# PIC32MK0512GPK100 device description
Architecture: MIPS; Family: PIC32MK; Series: PIC32MK
Registers are 32-bit, read-write, no defined reset value unless marked. A register's access mark holds for its fields unless they carry their own. Offsets are from the block's base; [hi:lo] are bit positions; 'fields as' and 'values as' point back to an identical list.

## GPIO
Instances: GPIO 0x1f860000 in periph_pb4_std
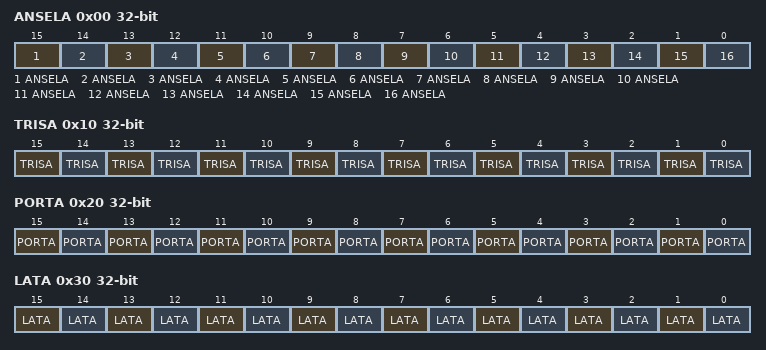
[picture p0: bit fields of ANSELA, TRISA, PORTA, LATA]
0x00 ANSELA
  [15] ANSELA, [14] ANSELA, [13] ANSELA, [12] ANSELA, [11] ANSELA, [10] ANSELA, [9] ANSELA, [8] ANSELA, [7] ANSELA, [6] ANSELA, [5] ANSELA, [4] ANSELA, [3] ANSELA, [2] ANSELA, [1] ANSELA, [0] ANSELA
0x10 TRISA
  [15] TRISA, [14] TRISA, [13] TRISA, [12] TRISA, [11] TRISA, [10] TRISA, [9] TRISA, [8] TRISA, [7] TRISA, [6] TRISA, [5] TRISA, [4] TRISA, [3] TRISA, [2] TRISA, [1] TRISA, [0] TRISA
0x20 PORTA
  [15] PORTA, [14] PORTA, [13] PORTA, [12] PORTA, [11] PORTA, [10] PORTA, [9] PORTA, [8] PORTA, [7] PORTA, [6] PORTA, [5] PORTA, [4] PORTA, [3] PORTA, [2] PORTA, [1] PORTA, [0] PORTA
0x30 LATA
  [15] LATA, [14] LATA, [13] LATA, [12] LATA, [11] LATA, [10] LATA, [9] LATA, [8] LATA, [7] LATA, [6] LATA, [5] LATA, [4] LATA, [3] LATA, [2] LATA, [1] LATA, [0] LATA
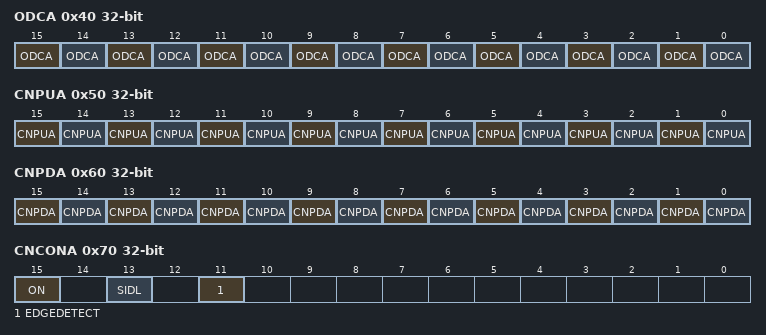
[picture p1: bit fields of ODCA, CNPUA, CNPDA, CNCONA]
0x40 ODCA
  [15] ODCA, [14] ODCA, [13] ODCA, [12] ODCA, [11] ODCA, [10] ODCA, [9] ODCA, [8] ODCA, [7] ODCA, [6] ODCA, [5] ODCA, [4] ODCA, [3] ODCA, [2] ODCA, [1] ODCA, [0] ODCA
0x50 CNPUA
  [15] CNPUA, [14] CNPUA, [13] CNPUA, [12] CNPUA, [11] CNPUA, [10] CNPUA, [9] CNPUA, [8] CNPUA, [7] CNPUA, [6] CNPUA, [5] CNPUA, [4] CNPUA, [3] CNPUA, [2] CNPUA, [1] CNPUA, [0] CNPUA
0x60 CNPDA
  [15] CNPDA, [14] CNPDA, [13] CNPDA, [12] CNPDA, [11] CNPDA, [10] CNPDA, [9] CNPDA, [8] CNPDA, [7] CNPDA, [6] CNPDA, [5] CNPDA, [4] CNPDA, [3] CNPDA, [2] CNPDA, [1] CNPDA, [0] CNPDA
0x70 CNCONA — Change Notice control for PORTx Register
  [15] ON — Change Notice Control ON bit
    1=CN is enabled; 0=CN is disabled
  [13] SIDL — Stop in Idle Control bit
    1=CPU Idle mode halts CN operation; 0=CPU Idle mode does not affect CN operation
  [11] EDGEDETECT — Change Notification Style bit
    1=Edge Style. Detect edge transitions (CNFx used for CN Event).; 0=Mismatch Style. Detect change from last PORTx read (CNSTATx used for CN Event).
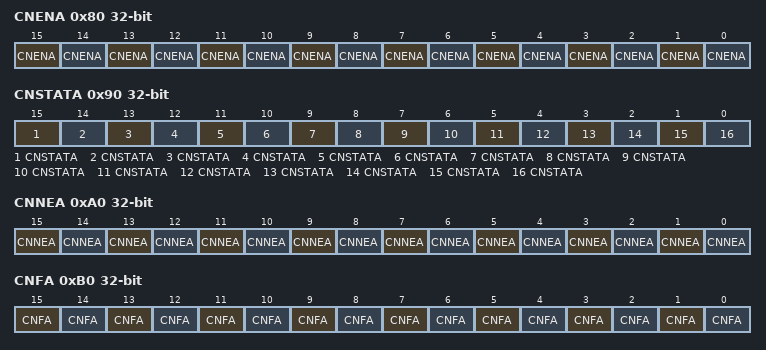
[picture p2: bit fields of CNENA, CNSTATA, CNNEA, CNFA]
0x80 CNENA
  [15] CNENA, [14] CNENA, [13] CNENA, [12] CNENA, [11] CNENA, [10] CNENA, [9] CNENA, [8] CNENA, [7] CNENA, [6] CNENA, [5] CNENA, [4] CNENA, [3] CNENA, [2] CNENA, [1] CNENA, [0] CNENA
0x90 CNSTATA
  [15] CNSTATA, [14] CNSTATA, [13] CNSTATA, [12] CNSTATA, [11] CNSTATA, [10] CNSTATA, [9] CNSTATA, [8] CNSTATA, [7] CNSTATA, [6] CNSTATA, [5] CNSTATA, [4] CNSTATA, [3] CNSTATA, [2] CNSTATA, [1] CNSTATA, [0] CNSTATA
0xA0 CNNEA
  [15] CNNEA, [14] CNNEA, [13] CNNEA, [12] CNNEA, [11] CNNEA, [10] CNNEA, [9] CNNEA, [8] CNNEA, [7] CNNEA, [6] CNNEA, [5] CNNEA, [4] CNNEA, [3] CNNEA, [2] CNNEA, [1] CNNEA, [0] CNNEA
0xB0 CNFA
  [15] CNFA, [14] CNFA, [13] CNFA, [12] CNFA, [11] CNFA, [10] CNFA, [9] CNFA, [8] CNFA, [7] CNFA, [6] CNFA, [5] CNFA, [4] CNFA, [3] CNFA, [2] CNFA, [1] CNFA, [0] CNFA
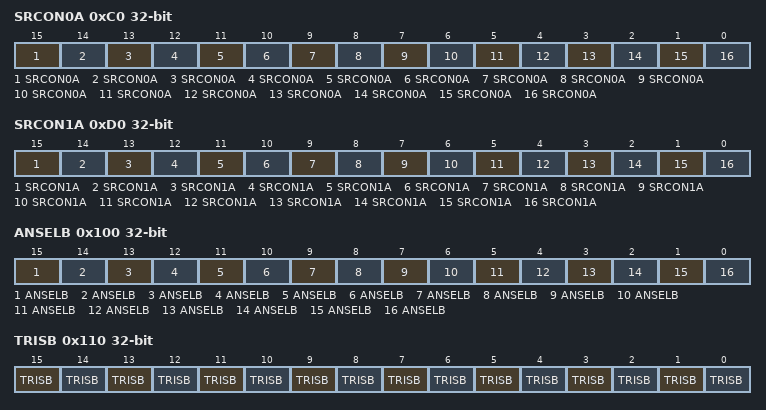
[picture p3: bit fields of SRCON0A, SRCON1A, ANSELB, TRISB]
0xC0 SRCON0A
  [15] SRCON0A, [14] SRCON0A, [13] SRCON0A, [12] SRCON0A, [11] SRCON0A, [10] SRCON0A, [9] SRCON0A, [8] SRCON0A, [7] SRCON0A, [6] SRCON0A, [5] SRCON0A, [4] SRCON0A, [3] SRCON0A, [2] SRCON0A, [1] SRCON0A, [0] SRCON0A
0xD0 SRCON1A
  [15] SRCON1A, [14] SRCON1A, [13] SRCON1A, [12] SRCON1A, [11] SRCON1A, [10] SRCON1A, [9] SRCON1A, [8] SRCON1A, [7] SRCON1A, [6] SRCON1A, [5] SRCON1A, [4] SRCON1A, [3] SRCON1A, [2] SRCON1A, [1] SRCON1A, [0] SRCON1A
0x100 ANSELB
  [15] ANSELB, [14] ANSELB, [13] ANSELB, [12] ANSELB, [11] ANSELB, [10] ANSELB, [9] ANSELB, [8] ANSELB, [7] ANSELB, [6] ANSELB, [5] ANSELB, [4] ANSELB, [3] ANSELB, [2] ANSELB, [1] ANSELB, [0] ANSELB
0x110 TRISB
  [15] TRISB, [14] TRISB, [13] TRISB, [12] TRISB, [11] TRISB, [10] TRISB, [9] TRISB, [8] TRISB, [7] TRISB, [6] TRISB, [5] TRISB, [4] TRISB, [3] TRISB, [2] TRISB, [1] TRISB, [0] TRISB
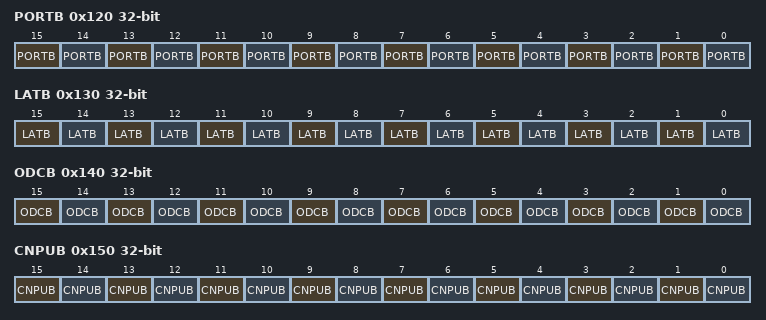
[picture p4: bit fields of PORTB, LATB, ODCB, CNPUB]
0x120 PORTB
  [15] PORTB, [14] PORTB, [13] PORTB, [12] PORTB, [11] PORTB, [10] PORTB, [9] PORTB, [8] PORTB, [7] PORTB, [6] PORTB, [5] PORTB, [4] PORTB, [3] PORTB, [2] PORTB, [1] PORTB, [0] PORTB
0x130 LATB
  [15] LATB, [14] LATB, [13] LATB, [12] LATB, [11] LATB, [10] LATB, [9] LATB, [8] LATB, [7] LATB, [6] LATB, [5] LATB, [4] LATB, [3] LATB, [2] LATB, [1] LATB, [0] LATB
0x140 ODCB
  [15] ODCB, [14] ODCB, [13] ODCB, [12] ODCB, [11] ODCB, [10] ODCB, [9] ODCB, [8] ODCB, [7] ODCB, [6] ODCB, [5] ODCB, [4] ODCB, [3] ODCB, [2] ODCB, [1] ODCB, [0] ODCB
0x150 CNPUB
  [15] CNPUB, [14] CNPUB, [13] CNPUB, [12] CNPUB, [11] CNPUB, [10] CNPUB, [9] CNPUB, [8] CNPUB, [7] CNPUB, [6] CNPUB, [5] CNPUB, [4] CNPUB, [3] CNPUB, [2] CNPUB, [1] CNPUB, [0] CNPUB
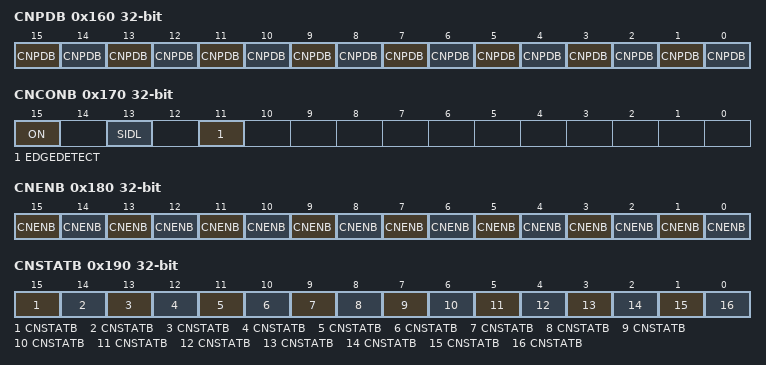
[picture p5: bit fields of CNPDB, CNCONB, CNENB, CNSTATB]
0x160 CNPDB
  [15] CNPDB, [14] CNPDB, [13] CNPDB, [12] CNPDB, [11] CNPDB, [10] CNPDB, [9] CNPDB, [8] CNPDB, [7] CNPDB, [6] CNPDB, [5] CNPDB, [4] CNPDB, [3] CNPDB, [2] CNPDB, [1] CNPDB, [0] CNPDB
0x170 CNCONB — Change Notice control for PORTx Register
  fields as CNCONA
0x180 CNENB
  [15] CNENB, [14] CNENB, [13] CNENB, [12] CNENB, [11] CNENB, [10] CNENB, [9] CNENB, [8] CNENB, [7] CNENB, [6] CNENB, [5] CNENB, [4] CNENB, [3] CNENB, [2] CNENB, [1] CNENB, [0] CNENB
0x190 CNSTATB
  [15] CNSTATB, [14] CNSTATB, [13] CNSTATB, [12] CNSTATB, [11] CNSTATB, [10] CNSTATB, [9] CNSTATB, [8] CNSTATB, [7] CNSTATB, [6] CNSTATB, [5] CNSTATB, [4] CNSTATB, [3] CNSTATB, [2] CNSTATB, [1] CNSTATB, [0] CNSTATB
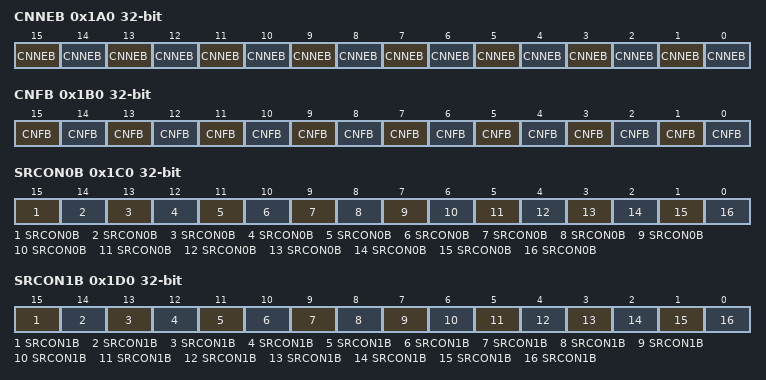
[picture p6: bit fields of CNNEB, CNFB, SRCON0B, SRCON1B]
0x1A0 CNNEB
  [15] CNNEB, [14] CNNEB, [13] CNNEB, [12] CNNEB, [11] CNNEB, [10] CNNEB, [9] CNNEB, [8] CNNEB, [7] CNNEB, [6] CNNEB, [5] CNNEB, [4] CNNEB, [3] CNNEB, [2] CNNEB, [1] CNNEB, [0] CNNEB
0x1B0 CNFB
  [15] CNFB, [14] CNFB, [13] CNFB, [12] CNFB, [11] CNFB, [10] CNFB, [9] CNFB, [8] CNFB, [7] CNFB, [6] CNFB, [5] CNFB, [4] CNFB, [3] CNFB, [2] CNFB, [1] CNFB, [0] CNFB
0x1C0 SRCON0B
  [15] SRCON0B, [14] SRCON0B, [13] SRCON0B, [12] SRCON0B, [11] SRCON0B, [10] SRCON0B, [9] SRCON0B, [8] SRCON0B, [7] SRCON0B, [6] SRCON0B, [5] SRCON0B, [4] SRCON0B, [3] SRCON0B, [2] SRCON0B, [1] SRCON0B, [0] SRCON0B
0x1D0 SRCON1B
  [15] SRCON1B, [14] SRCON1B, [13] SRCON1B, [12] SRCON1B, [11] SRCON1B, [10] SRCON1B, [9] SRCON1B, [8] SRCON1B, [7] SRCON1B, [6] SRCON1B, [5] SRCON1B, [4] SRCON1B, [3] SRCON1B, [2] SRCON1B, [1] SRCON1B, [0] SRCON1B
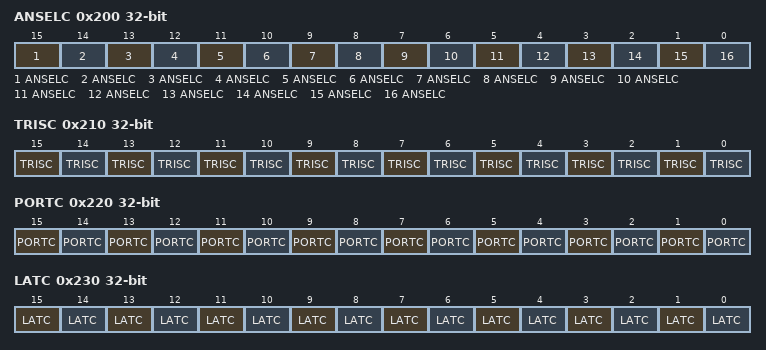
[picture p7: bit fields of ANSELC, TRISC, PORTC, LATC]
0x200 ANSELC
  [15] ANSELC, [14] ANSELC, [13] ANSELC, [12] ANSELC, [11] ANSELC, [10] ANSELC, [9] ANSELC, [8] ANSELC, [7] ANSELC, [6] ANSELC, [5] ANSELC, [4] ANSELC, [3] ANSELC, [2] ANSELC, [1] ANSELC, [0] ANSELC
0x210 TRISC
  [15] TRISC, [14] TRISC, [13] TRISC, [12] TRISC, [11] TRISC, [10] TRISC, [9] TRISC, [8] TRISC, [7] TRISC, [6] TRISC, [5] TRISC, [4] TRISC, [3] TRISC, [2] TRISC, [1] TRISC, [0] TRISC
0x220 PORTC
  [15] PORTC, [14] PORTC, [13] PORTC, [12] PORTC, [11] PORTC, [10] PORTC, [9] PORTC, [8] PORTC, [7] PORTC, [6] PORTC, [5] PORTC, [4] PORTC, [3] PORTC, [2] PORTC, [1] PORTC, [0] PORTC
0x230 LATC
  [15] LATC, [14] LATC, [13] LATC, [12] LATC, [11] LATC, [10] LATC, [9] LATC, [8] LATC, [7] LATC, [6] LATC, [5] LATC, [4] LATC, [3] LATC, [2] LATC, [1] LATC, [0] LATC
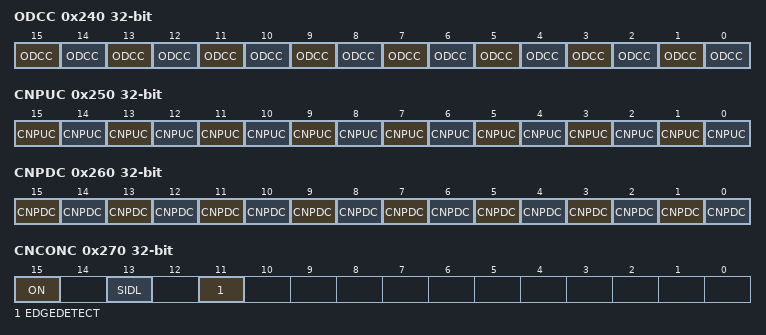
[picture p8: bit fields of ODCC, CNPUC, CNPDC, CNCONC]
0x240 ODCC
  [15] ODCC, [14] ODCC, [13] ODCC, [12] ODCC, [11] ODCC, [10] ODCC, [9] ODCC, [8] ODCC, [7] ODCC, [6] ODCC, [5] ODCC, [4] ODCC, [3] ODCC, [2] ODCC, [1] ODCC, [0] ODCC
0x250 CNPUC
  [15] CNPUC, [14] CNPUC, [13] CNPUC, [12] CNPUC, [11] CNPUC, [10] CNPUC, [9] CNPUC, [8] CNPUC, [7] CNPUC, [6] CNPUC, [5] CNPUC, [4] CNPUC, [3] CNPUC, [2] CNPUC, [1] CNPUC, [0] CNPUC
0x260 CNPDC
  [15] CNPDC, [14] CNPDC, [13] CNPDC, [12] CNPDC, [11] CNPDC, [10] CNPDC, [9] CNPDC, [8] CNPDC, [7] CNPDC, [6] CNPDC, [5] CNPDC, [4] CNPDC, [3] CNPDC, [2] CNPDC, [1] CNPDC, [0] CNPDC
0x270 CNCONC — Change Notice control for PORTx Register
  fields as CNCONA
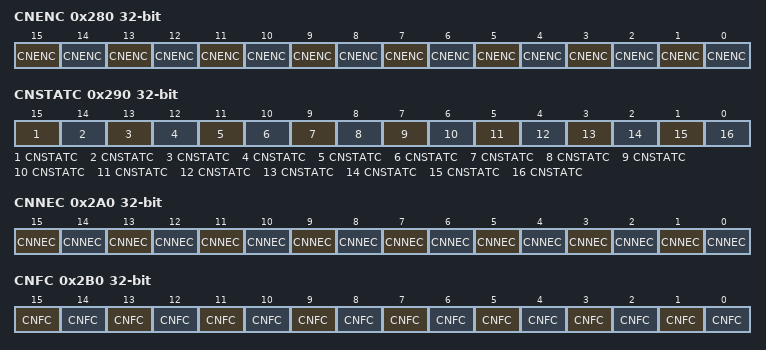
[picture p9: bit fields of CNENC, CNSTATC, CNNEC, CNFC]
0x280 CNENC
  [15] CNENC, [14] CNENC, [13] CNENC, [12] CNENC, [11] CNENC, [10] CNENC, [9] CNENC, [8] CNENC, [7] CNENC, [6] CNENC, [5] CNENC, [4] CNENC, [3] CNENC, [2] CNENC, [1] CNENC, [0] CNENC
0x290 CNSTATC
  [15] CNSTATC, [14] CNSTATC, [13] CNSTATC, [12] CNSTATC, [11] CNSTATC, [10] CNSTATC, [9] CNSTATC, [8] CNSTATC, [7] CNSTATC, [6] CNSTATC, [5] CNSTATC, [4] CNSTATC, [3] CNSTATC, [2] CNSTATC, [1] CNSTATC, [0] CNSTATC
0x2A0 CNNEC
  [15] CNNEC, [14] CNNEC, [13] CNNEC, [12] CNNEC, [11] CNNEC, [10] CNNEC, [9] CNNEC, [8] CNNEC, [7] CNNEC, [6] CNNEC, [5] CNNEC, [4] CNNEC, [3] CNNEC, [2] CNNEC, [1] CNNEC, [0] CNNEC
0x2B0 CNFC
  [15] CNFC, [14] CNFC, [13] CNFC, [12] CNFC, [11] CNFC, [10] CNFC, [9] CNFC, [8] CNFC, [7] CNFC, [6] CNFC, [5] CNFC, [4] CNFC, [3] CNFC, [2] CNFC, [1] CNFC, [0] CNFC
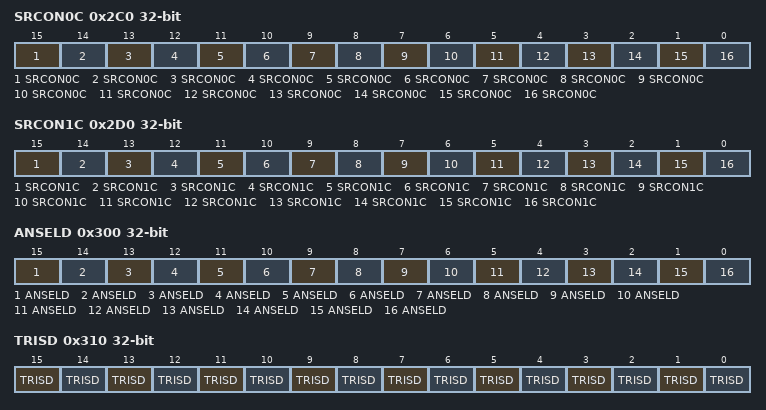
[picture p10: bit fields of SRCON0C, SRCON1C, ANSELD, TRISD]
0x2C0 SRCON0C
  [15] SRCON0C, [14] SRCON0C, [13] SRCON0C, [12] SRCON0C, [11] SRCON0C, [10] SRCON0C, [9] SRCON0C, [8] SRCON0C, [7] SRCON0C, [6] SRCON0C, [5] SRCON0C, [4] SRCON0C, [3] SRCON0C, [2] SRCON0C, [1] SRCON0C, [0] SRCON0C
0x2D0 SRCON1C
  [15] SRCON1C, [14] SRCON1C, [13] SRCON1C, [12] SRCON1C, [11] SRCON1C, [10] SRCON1C, [9] SRCON1C, [8] SRCON1C, [7] SRCON1C, [6] SRCON1C, [5] SRCON1C, [4] SRCON1C, [3] SRCON1C, [2] SRCON1C, [1] SRCON1C, [0] SRCON1C
0x300 ANSELD
  [15] ANSELD, [14] ANSELD, [13] ANSELD, [12] ANSELD, [11] ANSELD, [10] ANSELD, [9] ANSELD, [8] ANSELD, [7] ANSELD, [6] ANSELD, [5] ANSELD, [4] ANSELD, [3] ANSELD, [2] ANSELD, [1] ANSELD, [0] ANSELD
0x310 TRISD
  [15] TRISD, [14] TRISD, [13] TRISD, [12] TRISD, [11] TRISD, [10] TRISD, [9] TRISD, [8] TRISD, [7] TRISD, [6] TRISD, [5] TRISD, [4] TRISD, [3] TRISD, [2] TRISD, [1] TRISD, [0] TRISD
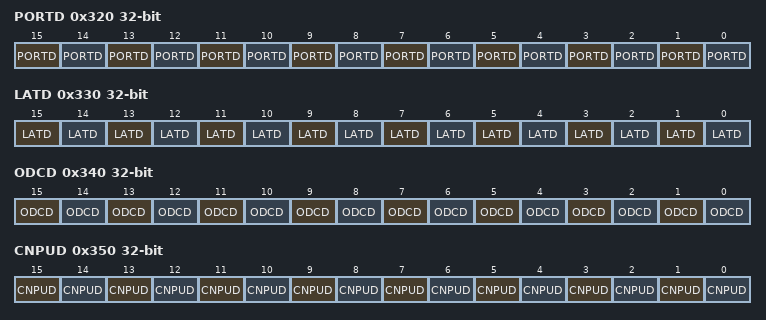
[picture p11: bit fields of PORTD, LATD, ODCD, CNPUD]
0x320 PORTD
  [15] PORTD, [14] PORTD, [13] PORTD, [12] PORTD, [11] PORTD, [10] PORTD, [9] PORTD, [8] PORTD, [7] PORTD, [6] PORTD, [5] PORTD, [4] PORTD, [3] PORTD, [2] PORTD, [1] PORTD, [0] PORTD
0x330 LATD
  [15] LATD, [14] LATD, [13] LATD, [12] LATD, [11] LATD, [10] LATD, [9] LATD, [8] LATD, [7] LATD, [6] LATD, [5] LATD, [4] LATD, [3] LATD, [2] LATD, [1] LATD, [0] LATD
0x340 ODCD
  [15] ODCD, [14] ODCD, [13] ODCD, [12] ODCD, [11] ODCD, [10] ODCD, [9] ODCD, [8] ODCD, [7] ODCD, [6] ODCD, [5] ODCD, [4] ODCD, [3] ODCD, [2] ODCD, [1] ODCD, [0] ODCD
0x350 CNPUD
  [15] CNPUD, [14] CNPUD, [13] CNPUD, [12] CNPUD, [11] CNPUD, [10] CNPUD, [9] CNPUD, [8] CNPUD, [7] CNPUD, [6] CNPUD, [5] CNPUD, [4] CNPUD, [3] CNPUD, [2] CNPUD, [1] CNPUD, [0] CNPUD
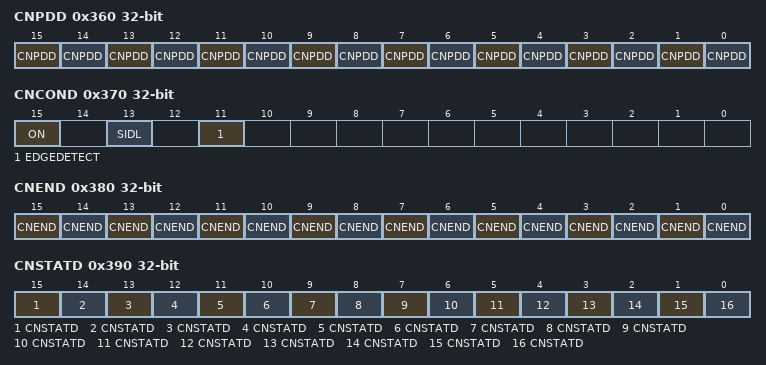
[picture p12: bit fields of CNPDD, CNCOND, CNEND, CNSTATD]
0x360 CNPDD
  [15] CNPDD, [14] CNPDD, [13] CNPDD, [12] CNPDD, [11] CNPDD, [10] CNPDD, [9] CNPDD, [8] CNPDD, [7] CNPDD, [6] CNPDD, [5] CNPDD, [4] CNPDD, [3] CNPDD, [2] CNPDD, [1] CNPDD, [0] CNPDD
0x370 CNCOND — Change Notice control for PORTx Register
  fields as CNCONA
0x380 CNEND
  [15] CNEND, [14] CNEND, [13] CNEND, [12] CNEND, [11] CNEND, [10] CNEND, [9] CNEND, [8] CNEND, [7] CNEND, [6] CNEND, [5] CNEND, [4] CNEND, [3] CNEND, [2] CNEND, [1] CNEND, [0] CNEND
0x390 CNSTATD
  [15] CNSTATD, [14] CNSTATD, [13] CNSTATD, [12] CNSTATD, [11] CNSTATD, [10] CNSTATD, [9] CNSTATD, [8] CNSTATD, [7] CNSTATD, [6] CNSTATD, [5] CNSTATD, [4] CNSTATD, [3] CNSTATD, [2] CNSTATD, [1] CNSTATD, [0] CNSTATD
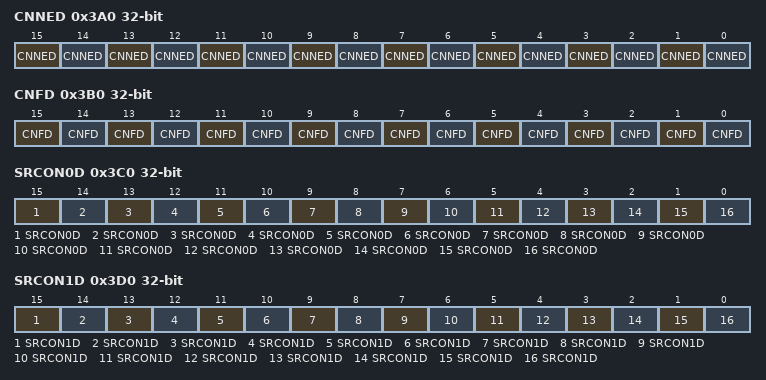
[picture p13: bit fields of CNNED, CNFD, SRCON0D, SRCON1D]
0x3A0 CNNED
  [15] CNNED, [14] CNNED, [13] CNNED, [12] CNNED, [11] CNNED, [10] CNNED, [9] CNNED, [8] CNNED, [7] CNNED, [6] CNNED, [5] CNNED, [4] CNNED, [3] CNNED, [2] CNNED, [1] CNNED, [0] CNNED
0x3B0 CNFD
  [15] CNFD, [14] CNFD, [13] CNFD, [12] CNFD, [11] CNFD, [10] CNFD, [9] CNFD, [8] CNFD, [7] CNFD, [6] CNFD, [5] CNFD, [4] CNFD, [3] CNFD, [2] CNFD, [1] CNFD, [0] CNFD
0x3C0 SRCON0D
  [15] SRCON0D, [14] SRCON0D, [13] SRCON0D, [12] SRCON0D, [11] SRCON0D, [10] SRCON0D, [9] SRCON0D, [8] SRCON0D, [7] SRCON0D, [6] SRCON0D, [5] SRCON0D, [4] SRCON0D, [3] SRCON0D, [2] SRCON0D, [1] SRCON0D, [0] SRCON0D
0x3D0 SRCON1D
  [15] SRCON1D, [14] SRCON1D, [13] SRCON1D, [12] SRCON1D, [11] SRCON1D, [10] SRCON1D, [9] SRCON1D, [8] SRCON1D, [7] SRCON1D, [6] SRCON1D, [5] SRCON1D, [4] SRCON1D, [3] SRCON1D, [2] SRCON1D, [1] SRCON1D, [0] SRCON1D
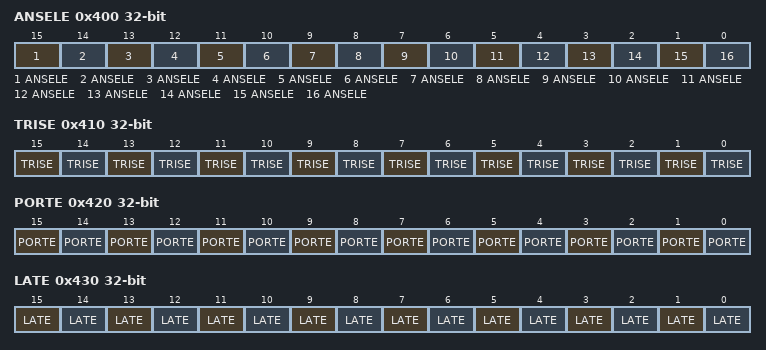
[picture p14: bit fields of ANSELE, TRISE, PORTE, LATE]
0x400 ANSELE
  [15] ANSELE, [14] ANSELE, [13] ANSELE, [12] ANSELE, [11] ANSELE, [10] ANSELE, [9] ANSELE, [8] ANSELE, [7] ANSELE, [6] ANSELE, [5] ANSELE, [4] ANSELE, [3] ANSELE, [2] ANSELE, [1] ANSELE, [0] ANSELE
0x410 TRISE
  [15] TRISE, [14] TRISE, [13] TRISE, [12] TRISE, [11] TRISE, [10] TRISE, [9] TRISE, [8] TRISE, [7] TRISE, [6] TRISE, [5] TRISE, [4] TRISE, [3] TRISE, [2] TRISE, [1] TRISE, [0] TRISE
0x420 PORTE
  [15] PORTE, [14] PORTE, [13] PORTE, [12] PORTE, [11] PORTE, [10] PORTE, [9] PORTE, [8] PORTE, [7] PORTE, [6] PORTE, [5] PORTE, [4] PORTE, [3] PORTE, [2] PORTE, [1] PORTE, [0] PORTE
0x430 LATE
  [15] LATE, [14] LATE, [13] LATE, [12] LATE, [11] LATE, [10] LATE, [9] LATE, [8] LATE, [7] LATE, [6] LATE, [5] LATE, [4] LATE, [3] LATE, [2] LATE, [1] LATE, [0] LATE
0x440 ODCE
  [15] ODCE, [14] ODCE, [13] ODCE, [12] ODCE, [11] ODCE, [10] ODCE, [9] ODCE, [8] ODCE, [7] ODCE, [6] ODCE, [5] ODCE, [4] ODCE, [3] ODCE, [2] ODCE, [1] ODCE, [0] ODCE
0x450 CNPUE
  [15] CNPUE, [14] CNPUE, [13] CNPUE, [12] CNPUE, [11] CNPUE, [10] CNPUE, [9] CNPUE, [8] CNPUE, [7] CNPUE, [6] CNPUE, [5] CNPUE, [4] CNPUE, [3] CNPUE, [2] CNPUE, [1] CNPUE, [0] CNPUE
0x460 CNPDE
  [15] CNPDE, [14] CNPDE, [13] CNPDE, [12] CNPDE, [11] CNPDE, [10] CNPDE, [9] CNPDE, [8] CNPDE, [7] CNPDE, [6] CNPDE, [5] CNPDE, [4] CNPDE, [3] CNPDE, [2] CNPDE, [1] CNPDE, [0] CNPDE
0x470 CNCONE — Change Notice control for PORTx Register
  fields as CNCONA
0x480 CNENE
  [15] CNENE, [14] CNENE, [13] CNENE, [12] CNENE, [11] CNENE, [10] CNENE, [9] CNENE, [8] CNENE, [7] CNENE, [6] CNENE, [5] CNENE, [4] CNENE, [3] CNENE, [2] CNENE, [1] CNENE, [0] CNENE
0x490 CNSTATE
  [15] CNSTATE, [14] CNSTATE, [13] CNSTATE, [12] CNSTATE, [11] CNSTATE, [10] CNSTATE, [9] CNSTATE, [8] CNSTATE, [7] CNSTATE, [6] CNSTATE, [5] CNSTATE, [4] CNSTATE, [3] CNSTATE, [2] CNSTATE, [1] CNSTATE, [0] CNSTATE
0x4A0 CNNEE
  [15] CNNEE, [14] CNNEE, [13] CNNEE, [12] CNNEE, [11] CNNEE, [10] CNNEE, [9] CNNEE, [8] CNNEE, [7] CNNEE, [6] CNNEE, [5] CNNEE, [4] CNNEE, [3] CNNEE, [2] CNNEE, [1] CNNEE, [0] CNNEE
0x4B0 CNFE
  [15] CNFE, [14] CNFE, [13] CNFE, [12] CNFE, [11] CNFE, [10] CNFE, [9] CNFE, [8] CNFE, [7] CNFE, [6] CNFE, [5] CNFE, [4] CNFE, [3] CNFE, [2] CNFE, [1] CNFE, [0] CNFE
0x4C0 SRCON0E
  [15] SRCON0E, [14] SRCON0E, [13] SRCON0E, [12] SRCON0E, [11] SRCON0E, [10] SRCON0E, [9] SRCON0E, [8] SRCON0E, [7] SRCON0E, [6] SRCON0E, [5] SRCON0E, [4] SRCON0E, [3] SRCON0E, [2] SRCON0E, [1] SRCON0E, [0] SRCON0E
0x4D0 SRCON1E
  [15] SRCON1E, [14] SRCON1E, [13] SRCON1E, [12] SRCON1E, [11] SRCON1E, [10] SRCON1E, [9] SRCON1E, [8] SRCON1E, [7] SRCON1E, [6] SRCON1E, [5] SRCON1E, [4] SRCON1E, [3] SRCON1E, [2] SRCON1E, [1] SRCON1E, [0] SRCON1E
0x500 ANSELF
  [15] ANSELF, [14] ANSELF, [13] ANSELF, [12] ANSELF, [11] ANSELF, [10] ANSELF, [9] ANSELF, [8] ANSELF, [7] ANSELF, [6] ANSELF, [5] ANSELF, [4] ANSELF, [3] ANSELF, [2] ANSELF, [1] ANSELF, [0] ANSELF
0x510 TRISF
  [15] TRISF, [14] TRISF, [13] TRISF, [12] TRISF, [11] TRISF, [10] TRISF, [9] TRISF, [8] TRISF, [7] TRISF, [6] TRISF, [5] TRISF, [4] TRISF, [3] TRISF, [2] TRISF, [1] TRISF, [0] TRISF
0x520 PORTF
  [15] PORTF, [14] PORTF, [13] PORTF, [12] PORTF, [11] PORTF, [10] PORTF, [9] PORTF, [8] PORTF, [7] PORTF, [6] PORTF, [5] PORTF, [4] PORTF, [3] PORTF, [2] PORTF, [1] PORTF, [0] PORTF
0x530 LATF
  [15] LATF, [14] LATF, [13] LATF, [12] LATF, [11] LATF, [10] LATF, [9] LATF, [8] LATF, [7] LATF, [6] LATF, [5] LATF, [4] LATF, [3] LATF, [2] LATF, [1] LATF, [0] LATF
0x540 ODCF
  [15] ODCF, [14] ODCF, [13] ODCF, [12] ODCF, [11] ODCF, [10] ODCF, [9] ODCF, [8] ODCF, [7] ODCF, [6] ODCF, [5] ODCF, [4] ODCF, [3] ODCF, [2] ODCF, [1] ODCF, [0] ODCF
0x550 CNPUF
  [15] CNPUF, [14] CNPUF, [13] CNPUF, [12] CNPUF, [11] CNPUF, [10] CNPUF, [9] CNPUF, [8] CNPUF, [7] CNPUF, [6] CNPUF, [5] CNPUF, [4] CNPUF, [3] CNPUF, [2] CNPUF, [1] CNPUF, [0] CNPUF
0x560 CNPDF
  [15] CNPDF, [14] CNPDF, [13] CNPDF, [12] CNPDF, [11] CNPDF, [10] CNPDF, [9] CNPDF, [8] CNPDF, [7] CNPDF, [6] CNPDF, [5] CNPDF, [4] CNPDF, [3] CNPDF, [2] CNPDF, [1] CNPDF, [0] CNPDF
0x570 CNCONF — Change Notice control for PORTx Register
  fields as CNCONA
0x580 CNENF
  [15] CNENF, [14] CNENF, [13] CNENF, [12] CNENF, [11] CNENF, [10] CNENF, [9] CNENF, [8] CNENF, [7] CNENF, [6] CNENF, [5] CNENF, [4] CNENF, [3] CNENF, [2] CNENF, [1] CNENF, [0] CNENF
0x590 CNSTATF
  [15] CNSTATF, [14] CNSTATF, [13] CNSTATF, [12] CNSTATF, [11] CNSTATF, [10] CNSTATF, [9] CNSTATF, [8] CNSTATF, [7] CNSTATF, [6] CNSTATF, [5] CNSTATF, [4] CNSTATF, [3] CNSTATF, [2] CNSTATF, [1] CNSTATF, [0] CNSTATF
0x5A0 CNNEF
  [15] CNNEF, [14] CNNEF, [13] CNNEF, [12] CNNEF, [11] CNNEF, [10] CNNEF, [9] CNNEF, [8] CNNEF, [7] CNNEF, [6] CNNEF, [5] CNNEF, [4] CNNEF, [3] CNNEF, [2] CNNEF, [1] CNNEF, [0] CNNEF
0x5B0 CNFF
  [15] CNFF, [14] CNFF, [13] CNFF, [12] CNFF, [11] CNFF, [10] CNFF, [9] CNFF, [8] CNFF, [7] CNFF, [6] CNFF, [5] CNFF, [4] CNFF, [3] CNFF, [2] CNFF, [1] CNFF, [0] CNFF
0x5C0 SRCON0F
  [15] SRCON0F, [14] SRCON0F, [13] SRCON0F, [12] SRCON0F, [11] SRCON0F, [10] SRCON0F, [9] SRCON0F, [8] SRCON0F, [7] SRCON0F, [6] SRCON0F, [5] SRCON0F, [4] SRCON0F, [3] SRCON0F, [2] SRCON0F, [1] SRCON0F, [0] SRCON0F
0x5D0 SRCON1F
  [15] SRCON1F, [14] SRCON1F, [13] SRCON1F, [12] SRCON1F, [11] SRCON1F, [10] SRCON1F, [9] SRCON1F, [8] SRCON1F, [7] SRCON1F, [6] SRCON1F, [5] SRCON1F, [4] SRCON1F, [3] SRCON1F, [2] SRCON1F, [1] SRCON1F, [0] SRCON1F
0x600 ANSELG
  [15] ANSELG, [14] ANSELG, [13] ANSELG, [12] ANSELG, [11] ANSELG, [10] ANSELG, [9] ANSELG, [8] ANSELG, [7] ANSELG, [6] ANSELG, [5] ANSELG, [4] ANSELG, [3] ANSELG, [2] ANSELG, [1] ANSELG, [0] ANSELG
0x610 TRISG
  [15] TRISG, [14] TRISG, [13] TRISG, [12] TRISG, [11] TRISG, [10] TRISG, [9] TRISG, [8] TRISG, [7] TRISG, [6] TRISG, [5] TRISG, [4] TRISG, [3] TRISG, [2] TRISG, [1] TRISG, [0] TRISG
0x620 PORTG
  [15] PORTG, [14] PORTG, [13] PORTG, [12] PORTG, [11] PORTG, [10] PORTG, [9] PORTG, [8] PORTG, [7] PORTG, [6] PORTG, [5] PORTG, [4] PORTG, [3] PORTG, [2] PORTG, [1] PORTG, [0] PORTG
0x630 LATG
  [15] LATG, [14] LATG, [13] LATG, [12] LATG, [11] LATG, [10] LATG, [9] LATG, [8] LATG, [7] LATG, [6] LATG, [5] LATG, [4] LATG, [3] LATG, [2] LATG, [1] LATG, [0] LATG
0x640 ODCG
  [15] ODCG, [14] ODCG, [13] ODCG, [12] ODCG, [11] ODCG, [10] ODCG, [9] ODCG, [8] ODCG, [7] ODCG, [6] ODCG, [5] ODCG, [4] ODCG, [3] ODCG, [2] ODCG, [1] ODCG, [0] ODCG
0x650 CNPUG
  [15] CNPUG, [14] CNPUG, [13] CNPUG, [12] CNPUG, [11] CNPUG, [10] CNPUG, [9] CNPUG, [8] CNPUG, [7] CNPUG, [6] CNPUG, [5] CNPUG, [4] CNPUG, [3] CNPUG, [2] CNPUG, [1] CNPUG, [0] CNPUG
0x660 CNPDG
  [15] CNPDG, [14] CNPDG, [13] CNPDG, [12] CNPDG, [11] CNPDG, [10] CNPDG, [9] CNPDG, [8] CNPDG, [7] CNPDG, [6] CNPDG, [5] CNPDG, [4] CNPDG, [3] CNPDG, [2] CNPDG, [1] CNPDG, [0] CNPDG
0x670 CNCONG — Change Notice control for PORTx Register
  fields as CNCONA
0x680 CNENG
  [15] CNENG, [14] CNENG, [13] CNENG, [12] CNENG, [11] CNENG, [10] CNENG, [9] CNENG, [8] CNENG, [7] CNENG, [6] CNENG, [5] CNENG, [4] CNENG, [3] CNENG, [2] CNENG, [1] CNENG, [0] CNENG
0x690 CNSTATG
  [15] CNSTATG, [14] CNSTATG, [13] CNSTATG, [12] CNSTATG, [11] CNSTATG, [10] CNSTATG, [9] CNSTATG, [8] CNSTATG, [7] CNSTATG, [6] CNSTATG, [5] CNSTATG, [4] CNSTATG, [3] CNSTATG, [2] CNSTATG, [1] CNSTATG, [0] CNSTATG
0x6A0 CNNEG
  [15] CNNEG, [14] CNNEG, [13] CNNEG, [12] CNNEG, [11] CNNEG, [10] CNNEG, [9] CNNEG, [8] CNNEG, [7] CNNEG, [6] CNNEG, [5] CNNEG, [4] CNNEG, [3] CNNEG, [2] CNNEG, [1] CNNEG, [0] CNNEG
0x6B0 CNFG
  [15] CNFG, [14] CNFG, [13] CNFG, [12] CNFG, [11] CNFG, [10] CNFG, [9] CNFG, [8] CNFG, [7] CNFG, [6] CNFG, [5] CNFG, [4] CNFG, [3] CNFG, [2] CNFG, [1] CNFG, [0] CNFG
